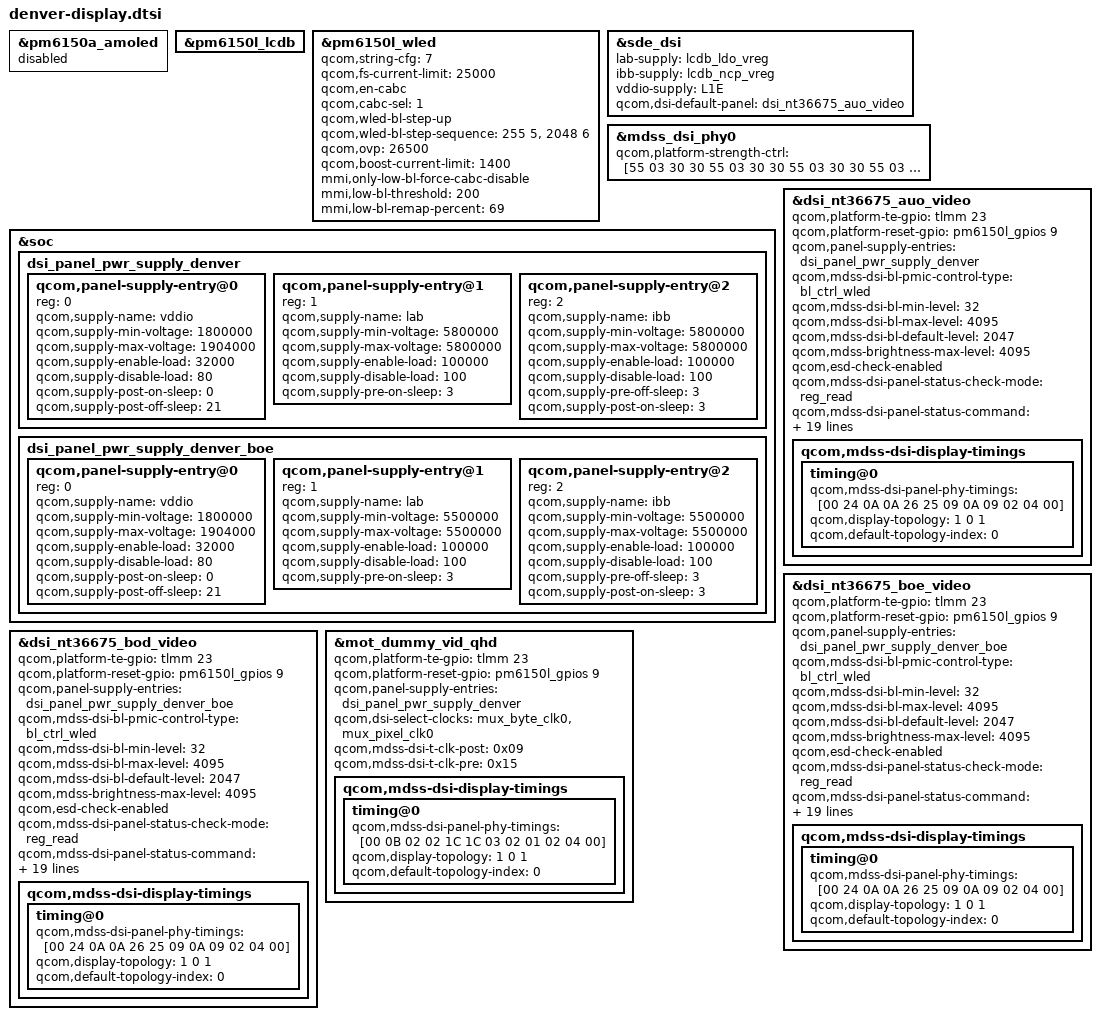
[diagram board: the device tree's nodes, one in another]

#include "dsi-panel-mot-auo-nt36675-fhd-video.dtsi"
#include "dsi-panel-mot-boe-nt36675-fhd-video.dtsi"
#include "dsi-panel-mot-dummy-qhd-video.dtsi"
#include "dsi-panel-mot-bod-nt36675-fhd-video.dtsi"



&pm6150a_amoled {
	status = "disabled";
};

&pm6150l_lcdb {
	status = "ok";
};

&pm6150l_wled {
	status = "ok";

	qcom,string-cfg = <7>;

	qcom,fs-current-limit = <25000>;
	qcom,en-cabc;
	qcom,cabc-sel = <1>;

	qcom,wled-bl-step-up;
	qcom,wled-bl-step-sequence = <255 5>, <2048 6>;

	qcom,ovp = <26500>;
	qcom,boost-current-limit = <1400>;

	mmi,only-low-bl-force-cabc-disable;
	mmi,low-bl-threshold = <200>;
	mmi,low-bl-remap-percent = <69>;
};

&sde_dsi {
	lab-supply = <&lcdb_ldo_vreg>;
	ibb-supply = <&lcdb_ncp_vreg>;
	vddio-supply = <&L1E>;

	qcom,dsi-default-panel = <&dsi_nt36675_auo_video>;
};

&mdss_dsi_phy0 {
	qcom,platform-strength-ctrl = [55 03 30 30
				55 03 30 30
				55 03 30 30
				55 03 30 30
				55 00 30 30];
};

&soc {
	dsi_panel_pwr_supply_denver: dsi_panel_pwr_supply_denver{
		#address-cells = <1>;
		#size-cells = <0>;

		qcom,panel-supply-entry@0 {
			reg = <0>;
			qcom,supply-name = "vddio";
			qcom,supply-min-voltage = <1800000>;
			qcom,supply-max-voltage = <1904000>;
			qcom,supply-enable-load = <32000>;
			qcom,supply-disable-load = <80>;
			qcom,supply-post-on-sleep= <0>;
			qcom,supply-post-off-sleep = <21>;
		};

		qcom,panel-supply-entry@1 {
			reg = <1>;
			qcom,supply-name = "lab";
			qcom,supply-min-voltage = <5800000>;
			qcom,supply-max-voltage = <5800000>;
			qcom,supply-enable-load = <100000>;
			qcom,supply-disable-load = <100>;
			qcom,supply-pre-on-sleep = <3>;
		};

		qcom,panel-supply-entry@2 {
			reg = <2>;
			qcom,supply-name = "ibb";
			qcom,supply-min-voltage = <5800000>;
			qcom,supply-max-voltage = <5800000>;
			qcom,supply-enable-load = <100000>;
			qcom,supply-disable-load = <100>;
			qcom,supply-pre-off-sleep = <3>;
			qcom,supply-post-on-sleep = <3>;
		};
	};

	dsi_panel_pwr_supply_denver_boe: dsi_panel_pwr_supply_denver_boe{
		#address-cells = <1>;
		#size-cells = <0>;

		qcom,panel-supply-entry@0 {
			reg = <0>;
			qcom,supply-name = "vddio";
			qcom,supply-min-voltage = <1800000>;
			qcom,supply-max-voltage = <1904000>;
			qcom,supply-enable-load = <32000>;
			qcom,supply-disable-load = <80>;
			qcom,supply-post-on-sleep= <0>;
			qcom,supply-post-off-sleep = <21>;
		};

		qcom,panel-supply-entry@1 {
			reg = <1>;
			qcom,supply-name = "lab";
			qcom,supply-min-voltage = <5500000>;
			qcom,supply-max-voltage = <5500000>;
			qcom,supply-enable-load = <100000>;
			qcom,supply-disable-load = <100>;
			qcom,supply-pre-on-sleep = <3>;
		};

		qcom,panel-supply-entry@2 {
			reg = <2>;
			qcom,supply-name = "ibb";
			qcom,supply-min-voltage = <5500000>;
			qcom,supply-max-voltage = <5500000>;
			qcom,supply-enable-load = <100000>;
			qcom,supply-disable-load = <100>;
			qcom,supply-pre-off-sleep = <3>;
			qcom,supply-post-on-sleep = <3>;
		};
	};
};

&dsi_nt36675_auo_video {
	qcom,platform-te-gpio = <&tlmm 23 0>;
	qcom,platform-reset-gpio = <&pm6150l_gpios 9 0>;

	qcom,panel-supply-entries = <&dsi_panel_pwr_supply_denver>;

	qcom,mdss-dsi-bl-pmic-control-type = "bl_ctrl_wled";

	qcom,mdss-dsi-bl-min-level = <32>;
	qcom,mdss-dsi-bl-max-level = <4095>;
	qcom,mdss-dsi-bl-default-level = <2047>;
	qcom,mdss-brightness-max-level = <4095>;

	qcom,esd-check-enabled;
	qcom,mdss-dsi-panel-status-check-mode = "reg_read";
	qcom,mdss-dsi-panel-status-command = [06 01 00 01 00 00 01 0a];
	qcom,mdss-dsi-panel-status-command-state = "dsi_hs_mode";
	qcom,mdss-dsi-panel-status-value = <0x9c>;
	qcom,mdss-dsi-panel-status-read-length = <1>;

	qcom,tp_state_check_enable;

	qcom,mdss-dsi-hbm-on-command = [39 01 00 00 00 00 03 51 0F FF];
	qcom,mdss-dsi-hbm-on-command-state = "dsi_lp_mode";
	qcom,mdss-dsi-hbm-off-command = [39 01 00 00 00 00 03 51 0B 13];
	qcom,mdss-dsi-hbm-off-command-state = "dsi_lp_mode";
	qcom,mdss-dsi-hbm-type = "lcd-dcs-wled";

	qcom,dsi-select-clocks = "mux_byte_clk0", "mux_pixel_clk0";
	qcom,mdss-dsi-t-clk-post = <0x0F>;
	qcom,mdss-dsi-t-clk-pre = <0x3B>;
	qcom,mdss-dsi-display-timings {
		timing@0 {
			qcom,mdss-dsi-panel-phy-timings = [00 24 0A 0A 26 25 09
				0A 09 02 04 00];
			qcom,display-topology = <1 0 1>;
			qcom,default-topology-index = <0>;
		};
	};
};

&dsi_nt36675_boe_video {
	qcom,platform-te-gpio = <&tlmm 23 0>;
	qcom,platform-reset-gpio = <&pm6150l_gpios 9 0>;

	qcom,panel-supply-entries = <&dsi_panel_pwr_supply_denver_boe>;

	qcom,mdss-dsi-bl-pmic-control-type = "bl_ctrl_wled";

	qcom,mdss-dsi-bl-min-level = <32>;
	qcom,mdss-dsi-bl-max-level = <4095>;
	qcom,mdss-dsi-bl-default-level = <2047>;
	qcom,mdss-brightness-max-level = <4095>;

	qcom,esd-check-enabled;
	qcom,mdss-dsi-panel-status-check-mode = "reg_read";
	qcom,mdss-dsi-panel-status-command = [06 01 00 01 00 00 01 0a];
	qcom,mdss-dsi-panel-status-command-state = "dsi_hs_mode";
	qcom,mdss-dsi-panel-status-value = <0x9c>;
	qcom,mdss-dsi-panel-status-read-length = <1>;

	qcom,tp_state_check_enable;

	qcom,mdss-dsi-hbm-on-command = [39 01 00 00 00 00 03 51 0F FF];
	qcom,mdss-dsi-hbm-on-command-state = "dsi_lp_mode";
	qcom,mdss-dsi-hbm-off-command = [39 01 00 00 00 00 03 51 0B 13];
	qcom,mdss-dsi-hbm-off-command-state = "dsi_lp_mode";
	qcom,mdss-dsi-hbm-type = "lcd-dcs-wled";

	qcom,dsi-select-clocks = "mux_byte_clk0", "mux_pixel_clk0";
	qcom,mdss-dsi-t-clk-post = <0x0F>;
	qcom,mdss-dsi-t-clk-pre = <0x3B>;
	qcom,mdss-dsi-display-timings {
		timing@0 {
			qcom,mdss-dsi-panel-phy-timings = [00 24 0A 0A 26 25 09
				0A 09 02 04 00];
			qcom,display-topology = <1 0 1>;
			qcom,default-topology-index = <0>;
		};
	};
};

&dsi_nt36675_bod_video {
	qcom,platform-te-gpio = <&tlmm 23 0>;
	qcom,platform-reset-gpio = <&pm6150l_gpios 9 0>;

	qcom,panel-supply-entries = <&dsi_panel_pwr_supply_denver_boe>;

	qcom,mdss-dsi-bl-pmic-control-type = "bl_ctrl_wled";

	qcom,mdss-dsi-bl-min-level = <32>;
	qcom,mdss-dsi-bl-max-level = <4095>;
	qcom,mdss-dsi-bl-default-level = <2047>;
	qcom,mdss-brightness-max-level = <4095>;

	qcom,esd-check-enabled;
	qcom,mdss-dsi-panel-status-check-mode = "reg_read";
	qcom,mdss-dsi-panel-status-command = [06 01 00 01 00 00 01 0a];
	qcom,mdss-dsi-panel-status-command-state = "dsi_hs_mode";
	qcom,mdss-dsi-panel-status-value = <0x9c>;
	qcom,mdss-dsi-panel-status-read-length = <1>;

	qcom,tp_state_check_enable;

	qcom,mdss-dsi-hbm-on-command = [39 01 00 00 00 00 03 51 0F FF];
	qcom,mdss-dsi-hbm-on-command-state = "dsi_lp_mode";
	qcom,mdss-dsi-hbm-off-command = [39 01 00 00 00 00 03 51 0B 13];
	qcom,mdss-dsi-hbm-off-command-state = "dsi_lp_mode";
	qcom,mdss-dsi-hbm-type = "lcd-dcs-wled";

	qcom,dsi-select-clocks = "mux_byte_clk0", "mux_pixel_clk0";
	qcom,mdss-dsi-t-clk-post = <0x0F>;
	qcom,mdss-dsi-t-clk-pre = <0x3B>;
	qcom,mdss-dsi-display-timings {
		timing@0 {
			qcom,mdss-dsi-panel-phy-timings = [00 24 0A 0A 26 25 09
				0A 09 02 04 00];
			qcom,display-topology = <1 0 1>;
			qcom,default-topology-index = <0>;
		};
	};
};

&mot_dummy_vid_qhd {
	qcom,platform-te-gpio = <&tlmm 23 0>;
	qcom,platform-reset-gpio = <&pm6150l_gpios 9 0>;

	qcom,panel-supply-entries = <&dsi_panel_pwr_supply_denver>;

	qcom,dsi-select-clocks = "mux_byte_clk0", "mux_pixel_clk0";
	qcom,mdss-dsi-t-clk-post = <0x09>;
	qcom,mdss-dsi-t-clk-pre = <0x15>;
	qcom,mdss-dsi-display-timings {
		timing@0 {
			qcom,mdss-dsi-panel-phy-timings = [00 0B 02 02 1C 1C 03
							02 01 02 04 00];
			qcom,display-topology = <1 0 1>;
			qcom,default-topology-index = <0>;
		};
	};
};
